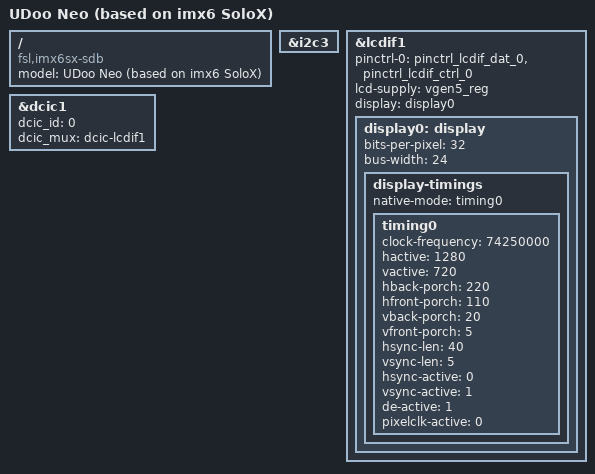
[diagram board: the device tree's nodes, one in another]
/*
 * Copyright (C) 2015 Jasbir Matharu
 *
 * This program is free software; you can redistribute it and/or modify
 * it under the terms of the GNU General Public License version 2 as
 * published by the Free Software Foundation.
 */


/dts-v1/;

#include "imx6sx-udoo-neo.dtsi"

/ {
	model = "UDoo Neo (based on imx6 SoloX)";
   	compatible = "fsl,imx6sx-sdb", "fsl,imx6sx";
};

&i2c3 {
	status = "okay";
};

&lcdif1 {
	pinctrl-names = "default";
	pinctrl-0 = <&pinctrl_lcdif_dat_0
		     &pinctrl_lcdif_ctrl_0>;
	lcd-supply = <&vgen5_reg>;
	display = <&display0>;
	status = "okay";

	display0: display {
		bits-per-pixel = <32>;
		bus-width = <24>;

		display-timings {
			native-mode = <&timing0>;
			timing0: timing0 {
				clock-frequency = <74250000>;
				hactive = <1280>;
				vactive = <720>;
				hback-porch = <220>;
				hfront-porch = <110>;
				vback-porch = <20>;
				vfront-porch = <5>;
				hsync-len = <40>;
				vsync-len = <5>;

				hsync-active = <0>;
				vsync-active = <1>;				
				de-active = <1>;
				pixelclk-active = <0>;				
			};
		};
	};
};

&dcic1 {
	dcic_id = <0>;
	dcic_mux = "dcic-lcdif1";
	status = "okay";
};
